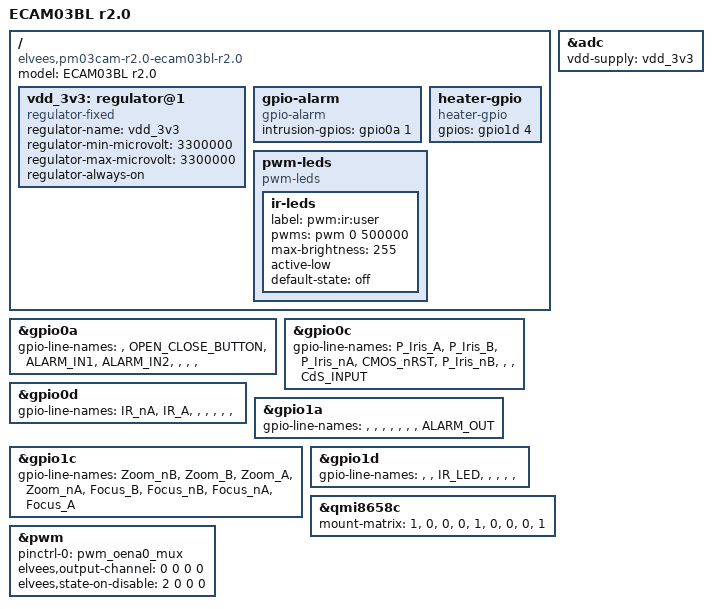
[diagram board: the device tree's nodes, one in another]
// SPDX-License-Identifier: GPL-2.0+
// Copyright 2023 RnD Center "ELVEES", JSC

/dts-v1/;

#include "mcom03-pm03cam-r2.0-ecam03common-r2.0.dts"

/ {
	model = "ECAM03BL r2.0";
	compatible = "elvees,pm03cam-r2.0-ecam03bl-r2.0",
		     "elvees,pm03cam-r2.0-ecam03common-r2.0",
		     "elvees,pm03cam-r2.0",
		     "elvees,mcom03";

	vdd_3v3: regulator@1 {
		compatible = "regulator-fixed";
		regulator-name = "vdd_3v3";
		regulator-min-microvolt = <3300000>;
		regulator-max-microvolt = <3300000>;
		regulator-always-on;
	};

	gpio-alarm {
		compatible = "gpio-alarm";
		intrusion-gpios = <&gpio0a 1 GPIO_ACTIVE_HIGH>;
	};

	heater-gpio {
		compatible = "heater-gpio";
		gpios = <&gpio1d 4 GPIO_ACTIVE_HIGH>;
	};

	pwm-leds {
		compatible = "pwm-leds";

		ir-leds {
			label = "pwm:ir:user";
			pwms = <&pwm 0 500000>;
			max-brightness = <255>;
			active-low;
			default-state = "off";
		};
	};
};

&gpio0a {
	gpio-line-names = "", "OPEN_CLOSE_BUTTON", "ALARM_IN1", "ALARM_IN2",
		"", "", "", "";
};

&gpio0c {
	gpio-line-names = "P_Iris_A", "P_Iris_B", "P_Iris_nA", "CMOS_nRST",
		"P_Iris_nB", "", "", "CdS_INPUT";
};

&gpio0d {
	gpio-line-names = "IR_nA", "IR_A", "", "", "", "", "", "";
};

&gpio1a {
	gpio-line-names = "", "", "", "",
		"", "", "", "ALARM_OUT";
};

&gpio1c {
	gpio-line-names = "Zoom_nB", "Zoom_B", "Zoom_A", "Zoom_nA",
		"Focus_B", "Focus_nB", "Focus_nA", "Focus_A";
};

&gpio1d {
	gpio-line-names = "", "", "IR_LED", "", "", "", "", "";
};

&adc {
	vdd-supply = <&vdd_3v3>;
};

&qmi8658c {
	mount-matrix = "1", "0", "0",
		       "0", "1", "0",
		       "0", "0", "1";
};

&pwm {
	status = "okay";

	pinctrl-names = "default";
	pinctrl-0 = <&pwm_oena0_mux>;

	elvees,output-channel = <0 0 0 0>;
	elvees,state-on-disable = <2 0 0 0>;
};
